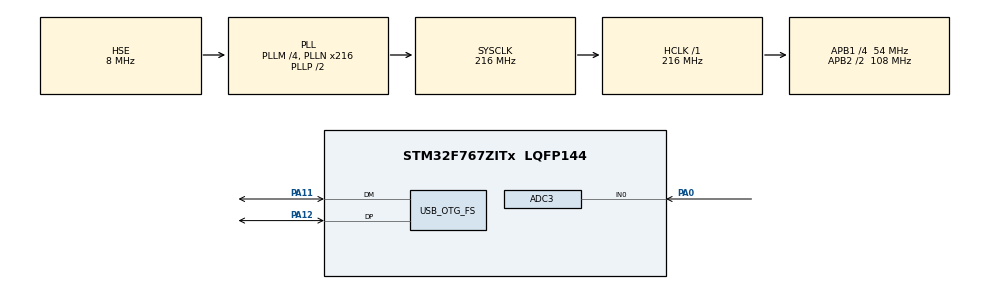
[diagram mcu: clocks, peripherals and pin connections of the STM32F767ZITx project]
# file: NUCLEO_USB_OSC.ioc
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ADC3.Channel-0\#ChannelRegularConversion=ADC_CHANNEL_0
ADC3.DMAContinuousRequests=ENABLE
ADC3.ExternalTrigConv=ADC_EXTERNALTRIGCONV_T2_CC2
ADC3.ExternalTrigConvEdge=ADC_EXTERNALTRIGCONVEDGE_RISINGFALLING
ADC3.NbrOfConversionFlag=1
ADC3.Rank-0\#ChannelRegularConversion=1
ADC3.SamplingTime-0\#ChannelRegularConversion=ADC_SAMPLETIME_144CYCLES
Dma.ADC3.0.Direction=DMA_PERIPH_TO_MEMORY
Dma.ADC3.0.FIFOMode=DMA_FIFOMODE_DISABLE
Dma.ADC3.0.Instance=DMA2_Stream0
Dma.ADC3.0.MemDataAlignment=DMA_MDATAALIGN_HALFWORD
Dma.ADC3.0.MemInc=DMA_MINC_ENABLE
Dma.ADC3.0.Mode=DMA_CIRCULAR
Dma.ADC3.0.PeriphDataAlignment=DMA_PDATAALIGN_HALFWORD
Dma.ADC3.0.PeriphInc=DMA_PINC_DISABLE
Dma.ADC3.0.Priority=DMA_PRIORITY_LOW
Dma.Request0=ADC3
Mcu.Family=STM32F7
Mcu.Name=STM32F767ZITx
Mcu.Package=LQFP144
NVIC.DMA2_Stream0_IRQn=true\:0\:0\:false\:false\:true\:false\:true
NVIC.OTG_FS_IRQn=true\:0\:0\:false\:false\:true\:false\:true
NVIC.PriorityGroup=NVIC_PRIORITYGROUP_4
PA0/WKUP.Signal=ADCx_IN0
PA11.Mode=Device_Only
PA11.Signal=USB_OTG_FS_DM
PA12.Mode=Device_Only
PA12.Signal=USB_OTG_FS_DP
PA13.Mode=Serial_Wire
PA13.Signal=SYS_JTMS-SWDIO
PA14.Mode=Serial_Wire
PA14.Signal=SYS_JTCK-SWCLK
PH0/OSC_IN.Mode=HSE-External-Clock-Source
PH0/OSC_IN.Signal=RCC_OSC_IN
PH1/OSC_OUT.Mode=HSE-External-Clock-Source
PH1/OSC_OUT.Signal=RCC_OSC_OUT
ProjectManager.HeapSize=0x2000
ProjectManager.StackSize=0x4000
ProjectManager.TargetToolchain=TrueSTUDIO
RCC.AHBFreq_Value=216000000
RCC.APB1CLKDivider=RCC_HCLK_DIV4
RCC.APB1Freq_Value=54000000
RCC.APB1TimFreq_Value=108000000
RCC.APB2CLKDivider=RCC_HCLK_DIV2
RCC.APB2Freq_Value=108000000
RCC.APB2TimFreq_Value=216000000
RCC.CortexFreq_Value=216000000
RCC.HCLKFreq_Value=216000000
RCC.HSE_VALUE=8000000
RCC.HSI_VALUE=16000000
RCC.LSE_VALUE=32768
RCC.PLLM=4
RCC.PLLN=216
RCC.PLLQ=9
RCC.SYSCLKFreq_VALUE=216000000
RCC.SYSCLKSource=RCC_SYSCLKSOURCE_PLLCLK
RCC.USBFreq_Value=48000000
RCC.VCOOutputFreq_Value=432000000
SH.ADCx_IN0.0=ADC3_IN0,IN0
TIM2.Channel-Output\ Compare2\ No\ Output=TIM_CHANNEL_2
TIM2.OCMode_2=TIM_OCMODE_TOGGLE
TIM2.Period=10799
USB_DEVICE.APP_RX_DATA_SIZE-CDC_FS=2048
USB_DEVICE.APP_TX_DATA_SIZE-CDC_FS=2048
USB_DEVICE.CLASS_NAME_FS=CDC
USB_DEVICE.PID_CDC_FS=21336
USB_DEVICE.USBD_LPM_ENABLED-CDC_FS=0
USB_DEVICE.USBD_MAX_STR_DESC_SIZ-CDC_FS=512
USB_DEVICE.USBD_SELF_POWERED-CDC_FS=0
USB_DEVICE.VirtualMode-CDC_FS=Cdc
USB_DEVICE.VirtualModeFS=Cdc_FS
USB_OTG_FS.VirtualMode=Device_Only
VP_TIM2_VS_ClockSourceINT.Mode=Internal
VP_TIM2_VS_no_output2.Mode=Output Compare2 No Output
VP_USB_DEVICE_VS_USB_DEVICE_CDC_FS.Mode=CDC_FS
board=custom

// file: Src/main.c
/* USER CODE BEGIN Header */
/**
  ******************************************************************************
  * @file           : main.c
  * @brief          : Main program body
  ******************************************************************************
  * @attention
  *
  * <h2><center>&copy; Copyright (c) 2019 STMicroelectronics.
  * All rights reserved.</center></h2>
  *
  * This software component is licensed by ST under Ultimate Liberty license
  * SLA0044, the "License"; You may not use this file except in compliance with
  * the License. You may obtain a copy of the License at:
  *                             www.st.com/SLA0044
  *
  ******************************************************************************
  */
/* USER CODE END Header */

#include "main.h"
#include "usb_device.h"

/* USER CODE BEGIN Includes */
#include "usbd_cdc_if.h"
/* USER CODE END Includes */

ADC_HandleTypeDef hadc3;
DMA_HandleTypeDef hdma_adc3;

TIM_HandleTypeDef htim2;

/* USER CODE BEGIN PV */
short aData0[1000];
uint8_t volatile AdcConversionDone = 0;

extern USBD_HandleTypeDef hUsbDeviceFS;
/* USER CODE END PV */

void SystemClock_Config(void);
static void MX_GPIO_Init(void);
static void MX_DMA_Init(void);
static void MX_ADC3_Init(void);
static void MX_TIM2_Init(void);
static void MX_GFXSIMULATOR_Init(void);

int main(void)
{

  /* MCU Configuration--------------------------------------------------------*/

  /* Reset of all peripherals, Initializes the Flash interface and the Systick. */
  HAL_Init();

  /* Configure the system clock */
  SystemClock_Config();

  /* Initialize all configured peripherals */
  MX_GPIO_Init();
  MX_DMA_Init();
  MX_ADC3_Init();
  MX_TIM2_Init();
  MX_GFXSIMULATOR_Init();
  MX_USB_DEVICE_Init();
  /* USER CODE BEGIN 2 */

  /*start ADC sampling into buffer*/
    HAL_ADC_Start_DMA(&hadc3, (uint32_t*)aData0, 1000);
    /*start TIM which triggers ADC conversions*/
    HAL_TIM_OC_Start(&htim2,TIM_CHANNEL_2);

  /* USER CODE END 2 */

  /* Infinite loop */
  while (1)
  {

    /* USER CODE BEGIN 3 */
	  if(AdcConversionDone>0)
	  {
		//CDC strucuture, where we check if the USB is transmithink
		USBD_CDC_HandleTypeDef   *hcdc;
		// if USB ready, and sent previous data we start transmitting
		if(hUsbDeviceFS.dev_state == USBD_STATE_CONFIGURED && (hcdc = hUsbDeviceFS.pClassData) != 0 && hcdc->TxState == 0){
		//send data over usb, we have 1000 16bit samples which is 2000bytes
		  CDC_Transmit_FS((uint8_t*)aData0,2000);
		//indicate that after we receive new data we can send more
		  AdcConversionDone=0;
		}
	  }
  }
  /* USER CODE END 3 */
}

void SystemClock_Config(void)
{
  RCC_OscInitTypeDef RCC_OscInitStruct = {0};
  RCC_ClkInitTypeDef RCC_ClkInitStruct = {0};
  RCC_PeriphCLKInitTypeDef PeriphClkInitStruct = {0};

  /** Configure the main internal regulator output voltage
  */
  __HAL_RCC_PWR_CLK_ENABLE();
  __HAL_PWR_VOLTAGESCALING_CONFIG(PWR_REGULATOR_VOLTAGE_SCALE1);
  /** Initializes the CPU, AHB and APB busses clocks
  */
  RCC_OscInitStruct.OscillatorType = RCC_OSCILLATORTYPE_HSE;
  RCC_OscInitStruct.HSEState = RCC_HSE_BYPASS;
  RCC_OscInitStruct.PLL.PLLState = RCC_PLL_ON;
  RCC_OscInitStruct.PLL.PLLSource = RCC_PLLSOURCE_HSE;
  RCC_OscInitStruct.PLL.PLLM = 4;
  RCC_OscInitStruct.PLL.PLLN = 216;
  RCC_OscInitStruct.PLL.PLLP = RCC_PLLP_DIV2;
  RCC_OscInitStruct.PLL.PLLQ = 9;
  if (HAL_RCC_OscConfig(&RCC_OscInitStruct) != HAL_OK)
  {
    Error_Handler();
  }
  /** Activate the Over-Drive mode
  */
  if (HAL_PWREx_EnableOverDrive() != HAL_OK)
  {
    Error_Handler();
  }
  /** Initializes the CPU, AHB and APB busses clocks
  */
  RCC_ClkInitStruct.ClockType = RCC_CLOCKTYPE_HCLK|RCC_CLOCKTYPE_SYSCLK
                              |RCC_CLOCKTYPE_PCLK1|RCC_CLOCKTYPE_PCLK2;
  RCC_ClkInitStruct.SYSCLKSource = RCC_SYSCLKSOURCE_PLLCLK;
  RCC_ClkInitStruct.AHBCLKDivider = RCC_SYSCLK_DIV1;
  RCC_ClkInitStruct.APB1CLKDivider = RCC_HCLK_DIV4;
  RCC_ClkInitStruct.APB2CLKDivider = RCC_HCLK_DIV2;

  if (HAL_RCC_ClockConfig(&RCC_ClkInitStruct, FLASH_LATENCY_7) != HAL_OK)
  {
    Error_Handler();
  }
  PeriphClkInitStruct.PeriphClockSelection = RCC_PERIPHCLK_CLK48;
  PeriphClkInitStruct.Clk48ClockSelection = RCC_CLK48SOURCE_PLL;
  if (HAL_RCCEx_PeriphCLKConfig(&PeriphClkInitStruct) != HAL_OK)
  {
    Error_Handler();
  }
}

static void MX_ADC3_Init(void)
{

  ADC_ChannelConfTypeDef sConfig = {0};

  /** Configure the global features of the ADC (Clock, Resolution, Data Alignment and number of conversion)
  */
  hadc3.Instance = ADC3;
  hadc3.Init.ClockPrescaler = ADC_CLOCK_SYNC_PCLK_DIV4;
  hadc3.Init.Resolution = ADC_RESOLUTION_12B;
  hadc3.Init.ScanConvMode = DISABLE;
  hadc3.Init.ContinuousConvMode = DISABLE;
  hadc3.Init.DiscontinuousConvMode = DISABLE;
  hadc3.Init.ExternalTrigConvEdge = ADC_EXTERNALTRIGCONVEDGE_RISINGFALLING;
  hadc3.Init.ExternalTrigConv = ADC_EXTERNALTRIGCONV_T2_CC2;
  hadc3.Init.DataAlign = ADC_DATAALIGN_RIGHT;
  hadc3.Init.NbrOfConversion = 1;
  hadc3.Init.DMAContinuousRequests = ENABLE;
  hadc3.Init.EOCSelection = ADC_EOC_SINGLE_CONV;
  if (HAL_ADC_Init(&hadc3) != HAL_OK)
  {
    Error_Handler();
  }
  /** Configure for the selected ADC regular channel its corresponding rank in the sequencer and its sample time.
  */
  sConfig.Channel = ADC_CHANNEL_0;
  sConfig.Rank = ADC_REGULAR_RANK_1;
  sConfig.SamplingTime = ADC_SAMPLETIME_144CYCLES;
  if (HAL_ADC_ConfigChannel(&hadc3, &sConfig) != HAL_OK)
  {
    Error_Handler();
  }

}

static void MX_GFXSIMULATOR_Init(void)
{

}

static void MX_TIM2_Init(void)
{

  TIM_ClockConfigTypeDef sClockSourceConfig = {0};
  TIM_MasterConfigTypeDef sMasterConfig = {0};
  TIM_OC_InitTypeDef sConfigOC = {0};

  htim2.Instance = TIM2;
  htim2.Init.Prescaler = 0;
  htim2.Init.CounterMode = TIM_COUNTERMODE_UP;
  htim2.Init.Period = 10799;
  htim2.Init.ClockDivision = TIM_CLOCKDIVISION_DIV1;
  htim2.Init.AutoReloadPreload = TIM_AUTORELOAD_PRELOAD_DISABLE;
  if (HAL_TIM_Base_Init(&htim2) != HAL_OK)
  {
    Error_Handler();
  }
  sClockSourceConfig.ClockSource = TIM_CLOCKSOURCE_INTERNAL;
  if (HAL_TIM_ConfigClockSource(&htim2, &sClockSourceConfig) != HAL_OK)
  {
    Error_Handler();
  }
  if (HAL_TIM_OC_Init(&htim2) != HAL_OK)
  {
    Error_Handler();
  }
  sMasterConfig.MasterOutputTrigger = TIM_TRGO_RESET;
  sMasterConfig.MasterSlaveMode = TIM_MASTERSLAVEMODE_DISABLE;
  if (HAL_TIMEx_MasterConfigSynchronization(&htim2, &sMasterConfig) != HAL_OK)
  {
    Error_Handler();
  }
  sConfigOC.OCMode = TIM_OCMODE_TOGGLE;
  sConfigOC.Pulse = 0;
  sConfigOC.OCPolarity = TIM_OCPOLARITY_HIGH;
  sConfigOC.OCFastMode = TIM_OCFAST_DISABLE;
  if (HAL_TIM_OC_ConfigChannel(&htim2, &sConfigOC, TIM_CHANNEL_2) != HAL_OK)
  {
    Error_Handler();
  }

}

static void MX_DMA_Init(void)
{
  /* DMA controller clock enable */
  __HAL_RCC_DMA2_CLK_ENABLE();

  /* DMA interrupt init */
  /* DMA2_Stream0_IRQn interrupt configuration */
  HAL_NVIC_SetPriority(DMA2_Stream0_IRQn, 0, 0);
  HAL_NVIC_EnableIRQ(DMA2_Stream0_IRQn);

}

static void MX_GPIO_Init(void)
{

  /* GPIO Ports Clock Enable */
  __HAL_RCC_GPIOH_CLK_ENABLE();
  __HAL_RCC_GPIOA_CLK_ENABLE();

}

/* USER CODE BEGIN 4 */
void HAL_ADC_ConvCpltCallback(ADC_HandleTypeDef* hadc)
{
  AdcConversionDone=1;
}
/* USER CODE END 4 */

void Error_Handler(void)
{
}

/************************ (C) COPYRIGHT STMicroelectronics *****END OF FILE****/
